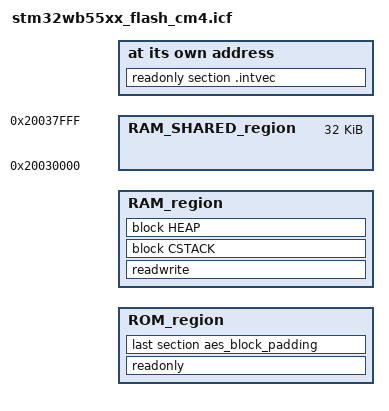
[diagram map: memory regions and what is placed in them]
/*###ICF### Set of symbols used in UserApp project ****/

define memory mem with size = 4G;

/******************************************************************************/
/*       Include of SBSFU symbols file                                        */
/*   (Project>Options>Linker>Extra Options --config_search option is used to  */
/*   specify the the directory to search for include files                    */
/******************************************************************************/
include "mapping_sbsfu.icf";
include "mapping_fwimg.icf";

/*-Specials-*/
define exported symbol __ICFEDIT_intvec_start__ = __ICFEDIT_SLOT_Active_1_start__ + 512;

/*-Memory Regions-*/

/***** FLASH Part dedicated to M4 *****/
define symbol __ICFEDIT_region_ROM_start__    = __ICFEDIT_intvec_start__;
define symbol __ICFEDIT_region_ROM_end__      = __ICFEDIT_SLOT_Active_1_end__ ;
/***** RAM1 dedicated to M4 *****/
define symbol __ICFEDIT_region_RAM_start__    = __ICFEDIT_SB_region_RAM_start__;
define symbol __ICFEDIT_region_RAM_end__      = __ICFEDIT_SB_region_RAM_end__  ;
/***** RAM2a *****/
define symbol __ICFEDIT_region_RAM_SHARED_start__  = 0x20030000  ;
define symbol __ICFEDIT_region_RAM_SHARED_end__    = 0x20037FFF  ;

/*-Sizes-*/
define symbol __ICFEDIT_size_cstack__ = 0x800;
define symbol __ICFEDIT_size_heap__   = 0x200;

define region ROM_region      = mem:[from __ICFEDIT_region_ROM_start__   to __ICFEDIT_region_ROM_end__];
define region RAM_region      = mem:[from __ICFEDIT_region_RAM_start__   to __ICFEDIT_region_RAM_end__];
define region RAM_SHARED_region    = mem:[from __ICFEDIT_region_RAM_SHARED_start__   to __ICFEDIT_region_RAM_SHARED_end__];

/* to make sure the binary size is a multiple of the AES block size (16 bytes) and WB flash writing unit (8 bytes) */
define root section aes_block_padding with alignment=16
{
udata8 "Force Alignment";
pad_to 16;
};

define block CSTACK    with alignment = 8, size = __ICFEDIT_size_cstack__   { };
define block HEAP      with alignment = 8, size = __ICFEDIT_size_heap__     { };

initialize by copy { readwrite };
do not initialize  { section .noinit };

place at address mem:__ICFEDIT_intvec_start__ { readonly section .intvec };

place in ROM_region   { readonly, last section aes_block_padding };
place in RAM_region   { readwrite, block CSTACK, block HEAP };
place in RAM_SHARED_region {};
